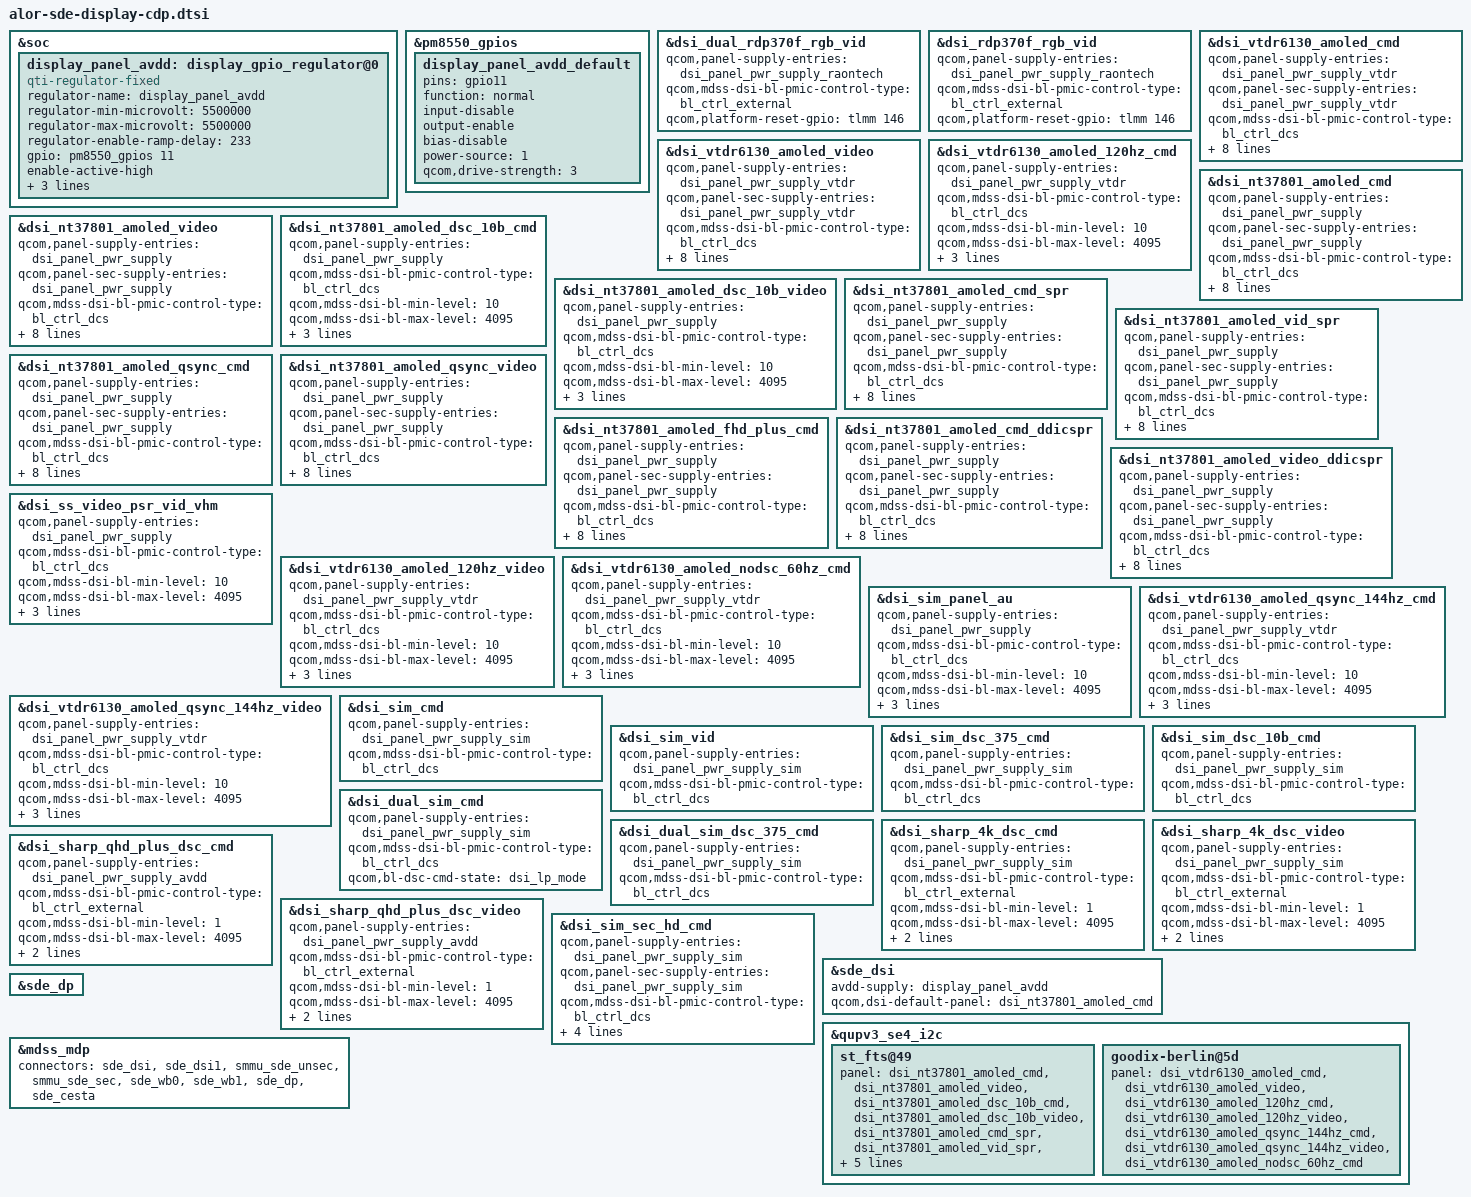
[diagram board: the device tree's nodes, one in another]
// SPDX-License-Identifier: BSD-3-Clause
/*
 * Copyright (c) Qualcomm Technologies, Inc. and/or its subsidiaries.
 */

#include "alor-sde-display.dtsi"

&soc {
	display_panel_avdd: display_gpio_regulator@0 {
		compatible = "qti-regulator-fixed";
		regulator-name = "display_panel_avdd";
		regulator-min-microvolt = <5500000>;
		regulator-max-microvolt = <5500000>;
		regulator-enable-ramp-delay = <233>;
		gpio = <&pm8550_gpios 11 0>;
		enable-active-high;
		regulator-boot-on;
		proxy-supply = <&display_panel_avdd>;
		qcom,proxy-consumer-enable;
		pinctrl-names = "default";
	};
};

&pm8550_gpios {
	display_panel_avdd_default: display_panel_avdd_default {
		pins = "gpio11";
		function = "normal";
		input-disable;
		output-enable;
		bias-disable;
		power-source = <1>;
		qcom,drive-strength = <3>;
	};
};

&dsi_dual_rdp370f_rgb_vid {
	qcom,panel-supply-entries = <&dsi_panel_pwr_supply_raontech>;
	qcom,mdss-dsi-bl-pmic-control-type = "bl_ctrl_external";
	qcom,platform-reset-gpio = <&tlmm 146 0>;
};

&dsi_rdp370f_rgb_vid {
	qcom,panel-supply-entries = <&dsi_panel_pwr_supply_raontech>;
	qcom,mdss-dsi-bl-pmic-control-type = "bl_ctrl_external";
	qcom,platform-reset-gpio = <&tlmm 146 0>;
};

&dsi_vtdr6130_amoled_cmd {
	qcom,panel-supply-entries = <&dsi_panel_pwr_supply_vtdr>;
	qcom,panel-sec-supply-entries = <&dsi_panel_pwr_supply_vtdr>;
	qcom,mdss-dsi-bl-pmic-control-type = "bl_ctrl_dcs";
	qcom,mdss-dsi-sec-bl-pmic-control-type = "bl_ctrl_dcs";
	qcom,mdss-dsi-bl-min-level = <10>;
	qcom,mdss-dsi-bl-max-level = <4095>;
	qcom,mdss-brightness-max-level = <8191>;
	qcom,mdss-dsi-bl-inverted-dbv;
	qcom,platform-reset-gpio = <&tlmm 146 0>;
	qcom,platform-sec-reset-gpio = <&tlmm 128 0>;
};

&dsi_vtdr6130_amoled_video {
	qcom,panel-supply-entries = <&dsi_panel_pwr_supply_vtdr>;
	qcom,panel-sec-supply-entries = <&dsi_panel_pwr_supply_vtdr>;
	qcom,mdss-dsi-bl-pmic-control-type = "bl_ctrl_dcs";
	qcom,mdss-dsi-sec-bl-pmic-control-type = "bl_ctrl_dcs";
	qcom,mdss-dsi-bl-min-level = <10>;
	qcom,mdss-dsi-bl-max-level = <4095>;
	qcom,mdss-brightness-max-level = <8191>;
	qcom,mdss-dsi-bl-inverted-dbv;
	qcom,platform-reset-gpio = <&tlmm 146 0>;
	qcom,platform-sec-reset-gpio = <&tlmm 128 0>;
};

&dsi_vtdr6130_amoled_120hz_cmd {
	qcom,panel-supply-entries = <&dsi_panel_pwr_supply_vtdr>;
	qcom,mdss-dsi-bl-pmic-control-type = "bl_ctrl_dcs";
	qcom,mdss-dsi-bl-min-level = <10>;
	qcom,mdss-dsi-bl-max-level = <4095>;
	qcom,mdss-brightness-max-level = <8191>;
	qcom,mdss-dsi-bl-inverted-dbv;
	qcom,platform-reset-gpio = <&tlmm 146 0>;
};

&dsi_nt37801_amoled_cmd {
	qcom,panel-supply-entries = <&dsi_panel_pwr_supply>;
	qcom,panel-sec-supply-entries = <&dsi_panel_pwr_supply>;
	qcom,mdss-dsi-bl-pmic-control-type = "bl_ctrl_dcs";
	qcom,mdss-dsi-sec-bl-pmic-control-type = "bl_ctrl_dcs";
	qcom,mdss-dsi-bl-min-level = <10>;
	qcom,mdss-dsi-bl-max-level = <4095>;
	qcom,mdss-brightness-max-level = <8191>;
	qcom,mdss-dsi-bl-inverted-dbv;
	qcom,platform-reset-gpio = <&tlmm 146 0>;
	qcom,platform-sec-reset-gpio = <&tlmm 128 0>;
};

&dsi_nt37801_amoled_video {
	qcom,panel-supply-entries = <&dsi_panel_pwr_supply>;
	qcom,panel-sec-supply-entries = <&dsi_panel_pwr_supply>;
	qcom,mdss-dsi-bl-pmic-control-type = "bl_ctrl_dcs";
	qcom,mdss-dsi-sec-bl-pmic-control-type = "bl_ctrl_dcs";
	qcom,mdss-dsi-bl-min-level = <10>;
	qcom,mdss-dsi-bl-max-level = <4095>;
	qcom,mdss-brightness-max-level = <8191>;
	qcom,mdss-dsi-bl-inverted-dbv;
	qcom,platform-reset-gpio = <&tlmm 146 0>;
	qcom,platform-sec-reset-gpio = <&tlmm 128 0>;
};

&dsi_nt37801_amoled_dsc_10b_cmd {
	qcom,panel-supply-entries = <&dsi_panel_pwr_supply>;
	qcom,mdss-dsi-bl-pmic-control-type = "bl_ctrl_dcs";
	qcom,mdss-dsi-bl-min-level = <10>;
	qcom,mdss-dsi-bl-max-level = <4095>;
	qcom,mdss-brightness-max-level = <8191>;
	qcom,mdss-dsi-bl-inverted-dbv;
	qcom,platform-reset-gpio = <&tlmm 146 0>;
};

&dsi_nt37801_amoled_dsc_10b_video {
	qcom,panel-supply-entries = <&dsi_panel_pwr_supply>;
	qcom,mdss-dsi-bl-pmic-control-type = "bl_ctrl_dcs";
	qcom,mdss-dsi-bl-min-level = <10>;
	qcom,mdss-dsi-bl-max-level = <4095>;
	qcom,mdss-brightness-max-level = <8191>;
	qcom,mdss-dsi-bl-inverted-dbv;
	qcom,platform-reset-gpio = <&tlmm 146 0>;
};

&dsi_nt37801_amoled_cmd_spr {
	qcom,panel-supply-entries = <&dsi_panel_pwr_supply>;
	qcom,panel-sec-supply-entries = <&dsi_panel_pwr_supply>;
	qcom,mdss-dsi-bl-pmic-control-type = "bl_ctrl_dcs";
	qcom,mdss-dsi-sec-bl-pmic-control-type = "bl_ctrl_dcs";
	qcom,mdss-dsi-bl-min-level = <10>;
	qcom,mdss-dsi-bl-max-level = <4095>;
	qcom,mdss-brightness-max-level = <8191>;
	qcom,mdss-dsi-bl-inverted-dbv;
	qcom,platform-reset-gpio = <&tlmm 146 0>;
	qcom,platform-sec-reset-gpio = <&tlmm 128 0>;
};

&dsi_nt37801_amoled_vid_spr {
	qcom,panel-supply-entries = <&dsi_panel_pwr_supply>;
	qcom,panel-sec-supply-entries = <&dsi_panel_pwr_supply>;
	qcom,mdss-dsi-bl-pmic-control-type = "bl_ctrl_dcs";
	qcom,mdss-dsi-sec-bl-pmic-control-type = "bl_ctrl_dcs";
	qcom,mdss-dsi-bl-min-level = <10>;
	qcom,mdss-dsi-bl-max-level = <4095>;
	qcom,mdss-brightness-max-level = <8191>;
	qcom,mdss-dsi-bl-inverted-dbv;
	qcom,platform-reset-gpio = <&tlmm 146 0>;
	qcom,platform-sec-reset-gpio = <&tlmm 128 0>;
};

&dsi_nt37801_amoled_qsync_cmd {
	qcom,panel-supply-entries = <&dsi_panel_pwr_supply>;
	qcom,panel-sec-supply-entries = <&dsi_panel_pwr_supply>;
	qcom,mdss-dsi-bl-pmic-control-type = "bl_ctrl_dcs";
	qcom,mdss-dsi-sec-bl-pmic-control-type = "bl_ctrl_dcs";
	qcom,mdss-dsi-bl-min-level = <10>;
	qcom,mdss-dsi-bl-max-level = <4095>;
	qcom,mdss-brightness-max-level = <8191>;
	qcom,mdss-dsi-bl-inverted-dbv;
	qcom,platform-reset-gpio = <&tlmm 146 0>;
	qcom,platform-sec-reset-gpio = <&tlmm 128 0>;
};

&dsi_nt37801_amoled_qsync_video {
	qcom,panel-supply-entries = <&dsi_panel_pwr_supply>;
	qcom,panel-sec-supply-entries = <&dsi_panel_pwr_supply>;
	qcom,mdss-dsi-bl-pmic-control-type = "bl_ctrl_dcs";
	qcom,mdss-dsi-sec-bl-pmic-control-type = "bl_ctrl_dcs";
	qcom,mdss-dsi-bl-min-level = <10>;
	qcom,mdss-dsi-bl-max-level = <4095>;
	qcom,mdss-brightness-max-level = <8191>;
	qcom,mdss-dsi-bl-inverted-dbv;
	qcom,platform-reset-gpio = <&tlmm 146 0>;
	qcom,platform-sec-reset-gpio = <&tlmm 128 0>;
};

&dsi_nt37801_amoled_fhd_plus_cmd {
	qcom,panel-supply-entries = <&dsi_panel_pwr_supply>;
	qcom,panel-sec-supply-entries = <&dsi_panel_pwr_supply>;
	qcom,mdss-dsi-bl-pmic-control-type = "bl_ctrl_dcs";
	qcom,mdss-dsi-sec-bl-pmic-control-type = "bl_ctrl_dcs";
	qcom,mdss-dsi-bl-min-level = <10>;
	qcom,mdss-dsi-bl-max-level = <4095>;
	qcom,mdss-brightness-max-level = <8191>;
	qcom,mdss-dsi-bl-inverted-dbv;
	qcom,platform-reset-gpio = <&tlmm 146 0>;
	qcom,platform-sec-reset-gpio = <&tlmm 128 0>;
};

&dsi_nt37801_amoled_cmd_ddicspr {
	qcom,panel-supply-entries = <&dsi_panel_pwr_supply>;
	qcom,panel-sec-supply-entries = <&dsi_panel_pwr_supply>;
	qcom,mdss-dsi-bl-pmic-control-type = "bl_ctrl_dcs";
	qcom,mdss-dsi-sec-bl-pmic-control-type = "bl_ctrl_dcs";
	qcom,mdss-dsi-bl-min-level = <10>;
	qcom,mdss-dsi-bl-max-level = <4095>;
	qcom,mdss-brightness-max-level = <8191>;
	qcom,mdss-dsi-bl-inverted-dbv;
	qcom,platform-reset-gpio = <&tlmm 146 0>;
	qcom,platform-sec-reset-gpio = <&tlmm 128 0>;
};

&dsi_nt37801_amoled_video_ddicspr {
	qcom,panel-supply-entries = <&dsi_panel_pwr_supply>;
	qcom,panel-sec-supply-entries = <&dsi_panel_pwr_supply>;
	qcom,mdss-dsi-bl-pmic-control-type = "bl_ctrl_dcs";
	qcom,mdss-dsi-sec-bl-pmic-control-type = "bl_ctrl_dcs";
	qcom,mdss-dsi-bl-min-level = <10>;
	qcom,mdss-dsi-bl-max-level = <4095>;
	qcom,mdss-brightness-max-level = <8191>;
	qcom,mdss-dsi-bl-inverted-dbv;
	qcom,platform-reset-gpio = <&tlmm 146 0>;
	qcom,platform-sec-reset-gpio = <&tlmm 128 0>;
};

&dsi_ss_video_psr_vid_vhm {
	qcom,panel-supply-entries = <&dsi_panel_pwr_supply>;
	qcom,mdss-dsi-bl-pmic-control-type = "bl_ctrl_dcs";
	qcom,mdss-dsi-bl-min-level = <10>;
	qcom,mdss-dsi-bl-max-level = <4095>;
	qcom,mdss-brightness-max-level = <8191>;
	qcom,mdss-dsi-bl-inverted-dbv;
	qcom,platform-reset-gpio = <&tlmm 146 0>;
};

&dsi_vtdr6130_amoled_120hz_video {
	qcom,panel-supply-entries = <&dsi_panel_pwr_supply_vtdr>;
	qcom,mdss-dsi-bl-pmic-control-type = "bl_ctrl_dcs";
	qcom,mdss-dsi-bl-min-level = <10>;
	qcom,mdss-dsi-bl-max-level = <4095>;
	qcom,mdss-brightness-max-level = <8191>;
	qcom,mdss-dsi-bl-inverted-dbv;
	qcom,platform-reset-gpio = <&tlmm 146 0>;
};

&dsi_vtdr6130_amoled_nodsc_60hz_cmd {
	qcom,panel-supply-entries = <&dsi_panel_pwr_supply_vtdr>;
	qcom,mdss-dsi-bl-pmic-control-type = "bl_ctrl_dcs";
	qcom,mdss-dsi-bl-min-level = <10>;
	qcom,mdss-dsi-bl-max-level = <4095>;
	qcom,mdss-brightness-max-level = <8191>;
	qcom,mdss-dsi-bl-inverted-dbv;
	qcom,platform-reset-gpio = <&tlmm 146 0>;
};

&dsi_sim_panel_au {
	qcom,panel-supply-entries = <&dsi_panel_pwr_supply>;
	qcom,mdss-dsi-bl-pmic-control-type = "bl_ctrl_dcs";
	qcom,mdss-dsi-bl-min-level = <10>;
	qcom,mdss-dsi-bl-max-level = <4095>;
	qcom,mdss-brightness-max-level = <8191>;
	qcom,mdss-dsi-bl-inverted-dbv;
	qcom,platform-reset-gpio = <&tlmm 146 0>;
};

&dsi_vtdr6130_amoled_qsync_144hz_cmd {
	qcom,panel-supply-entries = <&dsi_panel_pwr_supply_vtdr>;
	qcom,mdss-dsi-bl-pmic-control-type = "bl_ctrl_dcs";
	qcom,mdss-dsi-bl-min-level = <10>;
	qcom,mdss-dsi-bl-max-level = <4095>;
	qcom,mdss-brightness-max-level = <8191>;
	qcom,mdss-dsi-bl-inverted-dbv;
	qcom,platform-reset-gpio = <&tlmm 146 0>;
};

&dsi_vtdr6130_amoled_qsync_144hz_video {
	qcom,panel-supply-entries = <&dsi_panel_pwr_supply_vtdr>;
	qcom,mdss-dsi-bl-pmic-control-type = "bl_ctrl_dcs";
	qcom,mdss-dsi-bl-min-level = <10>;
	qcom,mdss-dsi-bl-max-level = <4095>;
	qcom,mdss-brightness-max-level = <8191>;
	qcom,mdss-dsi-bl-inverted-dbv;
	qcom,platform-reset-gpio = <&tlmm 146 0>;
};

&dsi_sim_cmd {
	qcom,panel-supply-entries = <&dsi_panel_pwr_supply_sim>;
	qcom,mdss-dsi-bl-pmic-control-type = "bl_ctrl_dcs";
};

&dsi_sim_vid {
	qcom,panel-supply-entries = <&dsi_panel_pwr_supply_sim>;
	qcom,mdss-dsi-bl-pmic-control-type = "bl_ctrl_dcs";
};

&dsi_sim_dsc_375_cmd {
	qcom,panel-supply-entries = <&dsi_panel_pwr_supply_sim>;
	qcom,mdss-dsi-bl-pmic-control-type = "bl_ctrl_dcs";
};

&dsi_sim_dsc_10b_cmd {
	qcom,panel-supply-entries = <&dsi_panel_pwr_supply_sim>;
	qcom,mdss-dsi-bl-pmic-control-type = "bl_ctrl_dcs";
};

&dsi_dual_sim_cmd {
	qcom,panel-supply-entries = <&dsi_panel_pwr_supply_sim>;
	qcom,mdss-dsi-bl-pmic-control-type = "bl_ctrl_dcs";
	qcom,bl-dsc-cmd-state = "dsi_lp_mode";
};

&dsi_dual_sim_dsc_375_cmd {
	qcom,panel-supply-entries = <&dsi_panel_pwr_supply_sim>;
	qcom,mdss-dsi-bl-pmic-control-type = "bl_ctrl_dcs";
};

&dsi_sharp_4k_dsc_cmd {
	qcom,panel-supply-entries = <&dsi_panel_pwr_supply_sim>;
	qcom,mdss-dsi-bl-pmic-control-type = "bl_ctrl_external";
	qcom,mdss-dsi-bl-min-level = <1>;
	qcom,mdss-dsi-bl-max-level = <4095>;
	qcom,platform-reset-gpio = <&tlmm 146 0>;
	qcom,platform-bklight-en-gpio = <&tlmm 54 0>;
};

&dsi_sharp_4k_dsc_video {
	qcom,panel-supply-entries = <&dsi_panel_pwr_supply_sim>;
	qcom,mdss-dsi-bl-pmic-control-type = "bl_ctrl_external";
	qcom,mdss-dsi-bl-min-level = <1>;
	qcom,mdss-dsi-bl-max-level = <4095>;
	qcom,platform-reset-gpio = <&tlmm 146 0>;
	qcom,platform-bklight-en-gpio = <&tlmm 54 0>;
};

&dsi_sharp_qhd_plus_dsc_cmd {
	qcom,panel-supply-entries = <&dsi_panel_pwr_supply_avdd>;
	qcom,mdss-dsi-bl-pmic-control-type = "bl_ctrl_external";
	qcom,mdss-dsi-bl-min-level = <1>;
	qcom,mdss-dsi-bl-max-level = <4095>;
	qcom,platform-reset-gpio = <&tlmm 146 0>;
	qcom,platform-bklight-en-gpio = <&tlmm 54 0>;
};

&dsi_sharp_qhd_plus_dsc_video {
	qcom,panel-supply-entries = <&dsi_panel_pwr_supply_avdd>;
	qcom,mdss-dsi-bl-pmic-control-type = "bl_ctrl_external";
	qcom,mdss-dsi-bl-min-level = <1>;
	qcom,mdss-dsi-bl-max-level = <4095>;
	qcom,platform-reset-gpio = <&tlmm 146 0>;
	qcom,platform-bklight-en-gpio = <&tlmm 54 0>;
};

&dsi_sim_sec_hd_cmd {
	qcom,panel-supply-entries = <&dsi_panel_pwr_supply_sim>;
	qcom,panel-sec-supply-entries = <&dsi_panel_pwr_supply_sim>;
	qcom,mdss-dsi-bl-pmic-control-type = "bl_ctrl_dcs";
	qcom,mdss-dsi-sec-bl-pmic-control-type = "bl_ctrl_dcs";
	qcom,mdss-dsi-bl-min-level = <1>;
	qcom,mdss-dsi-bl-max-level = <1023>;
};

&sde_dsi {
	avdd-supply = <&display_panel_avdd>;
	qcom,dsi-default-panel = <&dsi_nt37801_amoled_cmd>;
};

&qupv3_se4_i2c {
	st_fts@49 {
		panel = <&dsi_nt37801_amoled_cmd
			&dsi_nt37801_amoled_video
			&dsi_nt37801_amoled_dsc_10b_cmd
			&dsi_nt37801_amoled_dsc_10b_video
			&dsi_nt37801_amoled_cmd_spr
			&dsi_nt37801_amoled_vid_spr
			&dsi_nt37801_amoled_qsync_cmd
			&dsi_nt37801_amoled_qsync_video
			&dsi_nt37801_amoled_fhd_plus_cmd
			&dsi_nt37801_amoled_cmd_ddicspr
			&dsi_nt37801_amoled_video_ddicspr>;
	};

	goodix-berlin@5d {
		panel = <&dsi_vtdr6130_amoled_cmd
			&dsi_vtdr6130_amoled_video
			&dsi_vtdr6130_amoled_120hz_cmd
			&dsi_vtdr6130_amoled_120hz_video
			&dsi_vtdr6130_amoled_qsync_144hz_cmd
			&dsi_vtdr6130_amoled_qsync_144hz_video
			&dsi_vtdr6130_amoled_nodsc_60hz_cmd>;
	};
};

&sde_dp {
	status = "ok";
};

&mdss_mdp {
	connectors = <&sde_dsi &sde_dsi1 &smmu_sde_unsec &smmu_sde_sec
			&sde_wb0 &sde_wb1 &sde_dp &sde_cesta>;
};
